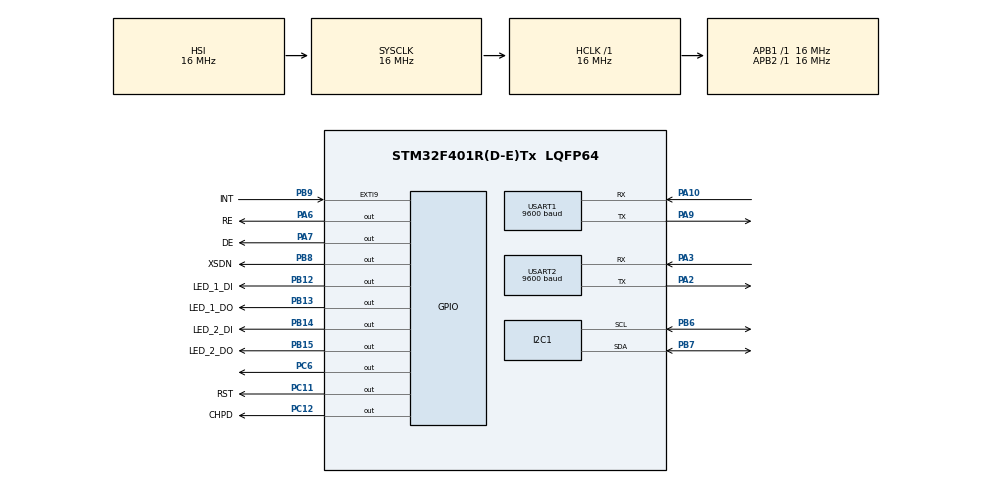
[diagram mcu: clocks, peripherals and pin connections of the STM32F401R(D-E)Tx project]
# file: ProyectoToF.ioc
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Mcu.Family=STM32F4
Mcu.Name=STM32F401R(D-E)Tx
Mcu.Package=LQFP64
NVIC.PriorityGroup=NVIC_PRIORITYGROUP_4
NVIC.USART1_IRQn=true\:0\:0\:false\:false\:true\:true\:true\:true
NVIC.USART2_IRQn=true\:0\:0\:false\:false\:true\:true\:true\:true
PA10.Mode=Asynchronous
PA10.Signal=USART1_RX
PA13.GPIO_Label=SDIO
PA13.Signal=SYS_JTMS-SWDIO
PA14.GPIO_Label=SCLK
PA14.Signal=SYS_JTCK-SWCLK
PA2.Mode=Asynchronous
PA2.Signal=USART2_TX
PA3.Mode=Asynchronous
PA3.Signal=USART2_RX
PA6.GPIO_Label=RE
PA6.Signal=GPIO_Output
PA7.GPIO_Label=DE
PA7.Signal=GPIO_Output
PA9.Mode=Asynchronous
PA9.Signal=USART1_TX
PB12.GPIO_Label=LED_1_DI
PB12.GPIO_Speed=GPIO_SPEED_FREQ_LOW
PB12.Signal=GPIO_Output
PB13.GPIO_Label=LED_1_DO
PB13.Signal=GPIO_Output
PB14.GPIO_Label=LED_2_DI
PB14.Signal=GPIO_Output
PB15.GPIO_Label=LED_2_DO
PB15.Signal=GPIO_Output
PB3.GPIO_Label=SWO
PB3.Signal=SYS_JTDO-SWO
PB6.GPIO_Pu=GPIO_PULLUP
PB6.Mode=I2C
PB6.Signal=I2C1_SCL
PB7.GPIO_Pu=GPIO_PULLUP
PB7.Mode=I2C
PB7.Signal=I2C1_SDA
PB8.GPIO_Label=XSDN
PB8.GPIO_PuPd=GPIO_NOPULL
PB8.Signal=GPIO_Output
PB9.GPIO_Label=INT
PB9.GPIO_PuPd=GPIO_PULLUP
PB9.Signal=GPXTI9
PC11.GPIO_Label=RST
PC11.Signal=GPIO_Output
PC12.GPIO_Label=CHPD
PC12.Signal=GPIO_Output
PC6.Signal=GPIO_Output
ProjectManager.HeapSize=0x200
ProjectManager.StackSize=0x400
ProjectManager.TargetToolchain=STM32CubeIDE
RCC.AHBFreq_Value=16000000
RCC.APB1Freq_Value=16000000
RCC.APB2Freq_Value=16000000
RCC.CortexFreq_Value=16000000
RCC.HSE_VALUE=25000000
RCC.HSI_VALUE=16000000
RCC.LSE_VALUE=32768
RCC.SYSCLKFreq_VALUE=16000000
RCC.VCOOutputFreq_Value=192000000
USART1.BaudRate=9600
USART1.VirtualMode=VM_ASYNC
USART2.BaudRate=9600
USART2.VirtualMode=VM_ASYNC
board=custom

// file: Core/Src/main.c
/* USER CODE BEGIN Header */
/**
  ******************************************************************************
  * @file           : main.c
  * @brief          : Main program body
  ******************************************************************************
  * @attention
  *
  * <h2><center>&copy; Copyright (c) 2020 STMicroelectronics.
  * All rights reserved.</center></h2>
  *
  * This software component is licensed by ST under BSD 3-Clause license,
  * the "License"; You may not use this file except in compliance with the
  * License. You may obtain a copy of the License at:
  *                        opensource.org/licenses/BSD-3-Clause
  *
  ******************************************************************************
  */
/* USER CODE END Header */
#include "main.h"
#include "stdio.h"
#include "stdint.h"
#include "string.h"
#include "PeopleCounter.h"
#include "handlers.h"

/* USER CODE BEGIN Includes */
VL53L1_DEV dev;
uint8_t	Dev=0x52;
int status = 0;
volatile int IntCount;
/* USER CODE END Includes */

/* USER CODE BEGIN PD */
#define window 15
/* USER CODE END PD */

/* USER CODE BEGIN PV */
I2C_HandleTypeDef hi2c1;
UART_HandleTypeDef huart1;
UART_HandleTypeDef huart2;
/* USER CODE END PV */

void SystemClock_Config(void);
static void MX_GPIO_Init(void);
static void MX_I2C1_Init(void);
static void MX_USART1_UART_Init(void);
static void MX_USART2_UART_Init(void);

int main(void)
{
  /* USER CODE BEGIN 1 */
	int8_t error;
	uint8_t byteData, sensorState=0;
	uint16_t wordData;
	uint16_t Distance;
	uint16_t avg_Distance;
	uint8_t RangeStatus;
	uint8_t dataReady;
	int center[2] = {167,231}; // these are the spad center of the 2 8*16 zones
	int Zone = 0;
	int PplCounter = 0;
	int lastPplCounter = 0;
	uint16_t measurements[window] = {0};

	uint8_t buf[128];
  /* USER CODE END 1 */

  /* MCU Configuration--------------------------------------------------------*/

  /* Reset of all peripherals, Initializes the Flash interface and the Systick. */
  HAL_Init();

  /* Configure the system clock */
  SystemClock_Config();

  /* Initialize all configured peripherals */
  MX_GPIO_Init();
  MX_I2C1_Init();
  MX_USART1_UART_Init();
  MX_USART2_UART_Init();
  /* USER CODE BEGIN 2 */
  HAL_GPIO_WritePin(GPIOC, GPIO_PIN_7, GPIO_PIN_SET);
  HAL_GPIO_WritePin(GPIOA, RE_Pin, 1);
  HAL_GPIO_WritePin(GPIOA, DE_Pin, 1);
  HAL_GPIO_WritePin(GPIOB, XSDN_Pin, 1);
  HAL_GPIO_WritePin(GPIOB, LED_1_DI_Pin, 0);
  HAL_GPIO_WritePin(GPIOB, LED_1_DO_Pin, 0);
  HAL_GPIO_WritePin(GPIOB, LED_2_DI_Pin, 0);
  HAL_GPIO_WritePin(GPIOB, LED_2_DO_Pin, 0);
  HAL_Delay(500);
  // Those basic I2C read functions can be used to check your own I2C functions
  status = VL53L1_RdByte(dev, 0x010F, &byteData);
  sprintf(buf,"VL53L1X Model_ID: %X\n", byteData);
  HAL_UART_Transmit(&huart1, buf, strlen((char*)buf), HAL_MAX_DELAY);
  status = VL53L1_RdByte(dev, 0x0110, &byteData);
  sprintf(buf,"VL53L1X Module_Type: %X\n", byteData);
  HAL_UART_Transmit(&huart1, buf, strlen((char*)buf), HAL_MAX_DELAY);
  status = VL53L1_RdWord(dev, 0x010F, &wordData);
  sprintf(buf,"VL53L1X: %X\n", wordData);
  HAL_UART_Transmit(&huart1, buf, strlen((char*)buf), HAL_MAX_DELAY);
  while (sensorState == 0) {
      status = VL53L1X_BootState(dev, &sensorState);
      HAL_Delay(2);
  }

  strcpy(buf,"Chip booted\n");
  HAL_UART_Transmit(&huart1, buf, strlen((char*)buf), HAL_MAX_DELAY);

  // Initialize and configure the device according to people counting need
  status = VL53L1X_SensorInit(dev);
  status += VL53L1X_SetDistanceMode(dev, 1); // 1=short, 2=long - PeopleCounter Mode 2
  status += VL53L1X_SetTimingBudgetInMs(dev, 20); // in ms possible values [20, 50, 100, 200, 500]
  status += VL53L1X_SetInterMeasurementInMs(dev, 20);
  status += VL53L1X_SetROI(dev, 4, 4); // minimum ROI 4,4 - PeopleCounter ROI 8,16
  if (status != 0) {
	  strcpy(buf,"Error in Initialization or configuration of the device\n");
	  HAL_UART_Transmit(&huart1, buf, strlen((char*)buf), HAL_MAX_DELAY);
      //return (-1);
  }

  strcpy(buf,"Start measuring oil level  ...\n");
  HAL_UART_Transmit(&huart1, buf, strlen((char*)buf), HAL_MAX_DELAY);
  status = VL53L1X_StartRanging(dev);   // This function has to be called to enable the ranging

  HAL_Delay(500);
  /* USER CODE END 2 */
  /* Infinite loop */
  /* USER CODE BEGIN WHILE */
  while (1)
  {
	    while (dataReady == 0) {
				status = VL53L1X_CheckForDataReady(dev, &dataReady);
				HAL_Delay(2);
	    }

			dataReady = 0;
			status += VL53L1X_GetRangeStatus(dev, &RangeStatus);
			status += VL53L1X_GetDistance(dev, &Distance);
			status += VL53L1X_ClearInterrupt(dev); /* clear interrupt has to be called to enable next interrupt*/
			if (status != 0) {
				strcpy(buf,"Error in operating the device\n");
				HAL_UART_Transmit(&huart1, buf, strlen((char*)buf), HAL_MAX_DELAY);
				//return (-1);
			}

			// wait a couple of milliseconds to ensure the setting of the new ROI center for the next ranging is effective
			// otherwise there is a risk that this setting is applied to current ranging (even if timing has expired, the intermeasurement
			// may expire immediately after.
			HAL_Delay(10);
			status = VL53L1X_SetROICenter(dev, center[Zone]);
			if (status != 0) {
				strcpy(buf,"Error in chaning the center of the ROI\n");
				HAL_UART_Transmit(&huart1, buf, strlen((char*)buf), HAL_MAX_DELAY);
				//return (-1);
			}

			// inject the new ranged distance in the people counting algorithm
			/*PplCounter = ProcessPeopleCountingData(Distance, Zone);
			Zone++;
			Zone = Zone%2;*/

			/*sprintf(buf,"Zone: %d, RangeStatus: %d, Distance: %d, Counter: %d\n", Zone, RangeStatus, Distance, PplCounter);
			HAL_UART_Transmit(&huart1, buf, strlen((char*)buf), HAL_MAX_DELAY);*/

			/*if(lastPplCounter != PplCounter) {
				sprintf(buf,"Zone: %d, RangeStatus: %d, Distance: %d, Counter: %d\n", Zone, RangeStatus, Distance, PplCounter);
				HAL_UART_Transmit(&huart1, buf, strlen((char*)buf), HAL_MAX_DELAY);
				lastPplCounter = PplCounter;
				  HAL_GPIO_TogglePin(GPIOB, LED_1_DO_Pin);
				  HAL_GPIO_TogglePin(GPIOB, LED_2_DO_Pin);
				  HAL_Delay(5);
				  HAL_GPIO_TogglePin(GPIOB, LED_1_DO_Pin);
				  HAL_GPIO_TogglePin(GPIOB, LED_2_DO_Pin);
			}*/

			if(1) {
				for(uint8_t i = 0; i < window-1; i++) {
					measurements[i] = measurements[i+1];
				}
				measurements[window-1] = Distance;
				avg_Distance = 0;
				for(uint8_t i = 0; i < window-1; i++) {
					avg_Distance += measurements[i];
				}
				avg_Distance = avg_Distance / window;
				if(avg_Distance>120){
					HAL_GPIO_WritePin(GPIOC, GPIO_PIN_7, GPIO_PIN_RESET);
				}else{
					HAL_GPIO_WritePin(GPIOC, GPIO_PIN_7, GPIO_PIN_SET);
				}
				sprintf(buf,"%d\r\n", avg_Distance);
				HAL_UART_Transmit(&huart1, buf, strlen((char*)buf), HAL_MAX_DELAY);
				HAL_GPIO_TogglePin(GPIOB, LED_1_DO_Pin);
				HAL_GPIO_TogglePin(GPIOB, LED_2_DO_Pin);
				HAL_Delay(5);
				HAL_GPIO_TogglePin(GPIOB, LED_1_DO_Pin);
				HAL_GPIO_TogglePin(GPIOB, LED_2_DO_Pin);
			}

			HAL_Delay(50);

  }
  /* USER CODE END 3 */
}

void SystemClock_Config(void)
{
  RCC_OscInitTypeDef RCC_OscInitStruct = {0};
  RCC_ClkInitTypeDef RCC_ClkInitStruct = {0};

  /** Configure the main internal regulator output voltage
  */
  __HAL_RCC_PWR_CLK_ENABLE();
  __HAL_PWR_VOLTAGESCALING_CONFIG(PWR_REGULATOR_VOLTAGE_SCALE2);
  /** Initializes the RCC Oscillators according to the specified parameters
  * in the RCC_OscInitTypeDef structure.
  */
  RCC_OscInitStruct.OscillatorType = RCC_OSCILLATORTYPE_HSI;
  RCC_OscInitStruct.HSIState = RCC_HSI_ON;
  RCC_OscInitStruct.HSICalibrationValue = RCC_HSICALIBRATION_DEFAULT;
  RCC_OscInitStruct.PLL.PLLState = RCC_PLL_NONE;
  if (HAL_RCC_OscConfig(&RCC_OscInitStruct) != HAL_OK)
  {
    Error_Handler();
  }
  /** Initializes the CPU, AHB and APB buses clocks
  */
  RCC_ClkInitStruct.ClockType = RCC_CLOCKTYPE_HCLK|RCC_CLOCKTYPE_SYSCLK
                              |RCC_CLOCKTYPE_PCLK1|RCC_CLOCKTYPE_PCLK2;
  RCC_ClkInitStruct.SYSCLKSource = RCC_SYSCLKSOURCE_HSI;
  RCC_ClkInitStruct.AHBCLKDivider = RCC_SYSCLK_DIV1;
  RCC_ClkInitStruct.APB1CLKDivider = RCC_HCLK_DIV1;
  RCC_ClkInitStruct.APB2CLKDivider = RCC_HCLK_DIV1;

  if (HAL_RCC_ClockConfig(&RCC_ClkInitStruct, FLASH_LATENCY_0) != HAL_OK)
  {
    Error_Handler();
  }
}

static void MX_I2C1_Init(void)
{

  hi2c1.Instance = I2C1;
  hi2c1.Init.ClockSpeed = 100000;
  hi2c1.Init.DutyCycle = I2C_DUTYCYCLE_2;
  hi2c1.Init.OwnAddress1 = 0;
  hi2c1.Init.AddressingMode = I2C_ADDRESSINGMODE_7BIT;
  hi2c1.Init.DualAddressMode = I2C_DUALADDRESS_DISABLE;
  hi2c1.Init.OwnAddress2 = 0;
  hi2c1.Init.GeneralCallMode = I2C_GENERALCALL_DISABLE;
  hi2c1.Init.NoStretchMode = I2C_NOSTRETCH_DISABLE;
  if (HAL_I2C_Init(&hi2c1) != HAL_OK)
  {
    Error_Handler();
  }

}

static void MX_USART1_UART_Init(void)
{

  huart1.Instance = USART1;
  huart1.Init.BaudRate = 9600;
  huart1.Init.WordLength = UART_WORDLENGTH_8B;
  huart1.Init.StopBits = UART_STOPBITS_1;
  huart1.Init.Parity = UART_PARITY_NONE;
  huart1.Init.Mode = UART_MODE_TX_RX;
  huart1.Init.HwFlowCtl = UART_HWCONTROL_NONE;
  huart1.Init.OverSampling = UART_OVERSAMPLING_16;
  if (HAL_UART_Init(&huart1) != HAL_OK)
  {
    Error_Handler();
  }

}

static void MX_USART2_UART_Init(void)
{

  huart2.Instance = USART2;
  huart2.Init.BaudRate = 9600;
  huart2.Init.WordLength = UART_WORDLENGTH_8B;
  huart2.Init.StopBits = UART_STOPBITS_1;
  huart2.Init.Parity = UART_PARITY_NONE;
  huart2.Init.Mode = UART_MODE_TX_RX;
  huart2.Init.HwFlowCtl = UART_HWCONTROL_NONE;
  huart2.Init.OverSampling = UART_OVERSAMPLING_16;
  if (HAL_UART_Init(&huart2) != HAL_OK)
  {
    Error_Handler();
  }

}

static void MX_GPIO_Init(void)
{
  GPIO_InitTypeDef GPIO_InitStruct = {0};

  /* GPIO Ports Clock Enable */
  __HAL_RCC_GPIOA_CLK_ENABLE();
  __HAL_RCC_GPIOB_CLK_ENABLE();
  __HAL_RCC_GPIOC_CLK_ENABLE();

  /*Configure GPIO pin Output Level */
  HAL_GPIO_WritePin(GPIOA, RE_Pin|DE_Pin, GPIO_PIN_RESET);

  /*Configure GPIO pin Output Level */
  HAL_GPIO_WritePin(GPIOB, LED_1_DI_Pin|LED_1_DO_Pin|LED_2_DI_Pin|LED_2_DO_Pin
                          |XSDN_Pin, GPIO_PIN_RESET);

  /*Configure GPIO pin Output Level */
  HAL_GPIO_WritePin(GPIOC, RST_Pin|CHPD_Pin, GPIO_PIN_RESET);

  /*Configure GPIO pins : RE_Pin DE_Pin */
  GPIO_InitStruct.Pin = RE_Pin|DE_Pin;
  GPIO_InitStruct.Mode = GPIO_MODE_OUTPUT_PP;
  GPIO_InitStruct.Pull = GPIO_NOPULL;
  GPIO_InitStruct.Speed = GPIO_SPEED_FREQ_LOW;
  HAL_GPIO_Init(GPIOA, &GPIO_InitStruct);

  /*Configure GPIO pins : LED_1_DI_Pin LED_1_DO_Pin LED_2_DI_Pin LED_2_DO_Pin
                           XSDN_Pin */
  GPIO_InitStruct.Pin = LED_1_DI_Pin|LED_1_DO_Pin|LED_2_DI_Pin|LED_2_DO_Pin
                          |XSDN_Pin;
  GPIO_InitStruct.Mode = GPIO_MODE_OUTPUT_PP;
  GPIO_InitStruct.Pull = GPIO_NOPULL;
  GPIO_InitStruct.Speed = GPIO_SPEED_FREQ_LOW;
  HAL_GPIO_Init(GPIOB, &GPIO_InitStruct);

  /*Configure GPIO pins : RST_Pin CHPD_Pin */
  GPIO_InitStruct.Pin = GPIO_PIN_7|RST_Pin|CHPD_Pin;
  GPIO_InitStruct.Mode = GPIO_MODE_OUTPUT_PP;
  GPIO_InitStruct.Pull = GPIO_NOPULL;
  GPIO_InitStruct.Speed = GPIO_SPEED_FREQ_LOW;
  HAL_GPIO_Init(GPIOC, &GPIO_InitStruct);

  /*Configure GPIO pin : INT_Pin */
  GPIO_InitStruct.Pin = INT_Pin;
  GPIO_InitStruct.Mode = GPIO_MODE_IT_RISING;
  GPIO_InitStruct.Pull = GPIO_PULLUP;
  HAL_GPIO_Init(INT_GPIO_Port, &GPIO_InitStruct);

}

void Error_Handler(void)
{
  __disable_irq();
  while (1)
  {
  }
}

/************************ (C) COPYRIGHT STMicroelectronics *****END OF FILE****/
